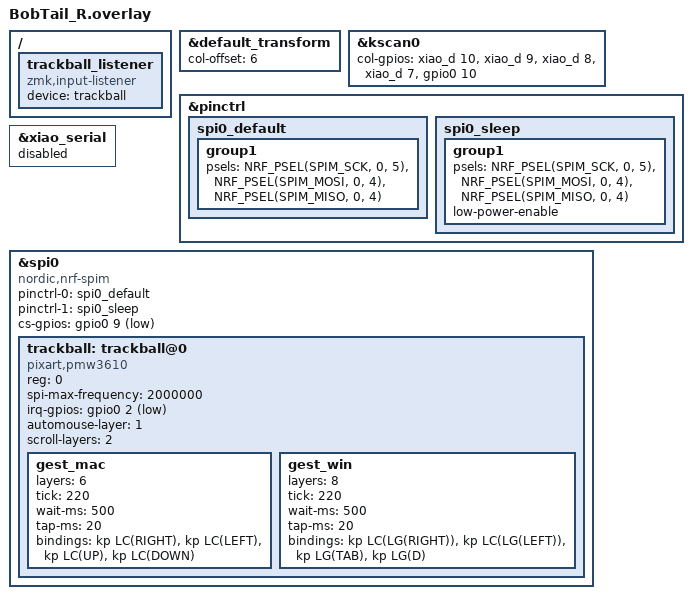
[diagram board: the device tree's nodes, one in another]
#include "BobTail.dtsi"
#include <dt-bindings/zmk/keys.h>

&default_transform {
    col-offset = <6>;
};

&kscan0 {
        col-gpios
            = <&xiao_d 10 GPIO_ACTIVE_HIGH>
            , <&xiao_d 9 GPIO_ACTIVE_HIGH> 
            , <&xiao_d 8 GPIO_ACTIVE_HIGH> 
            , <&xiao_d 7 GPIO_ACTIVE_HIGH> 
            , <&gpio0 10 GPIO_ACTIVE_HIGH>
            ;
};

/ {
    trackball_listener {
        compatible = "zmk,input-listener";
        device = <&trackball>;

    };
};

&pinctrl {
    spi0_default: spi0_default {
        group1 {
            psels = <NRF_PSEL(SPIM_SCK, 0, 5)>,
                <NRF_PSEL(SPIM_MOSI, 0, 4)>,
                <NRF_PSEL(SPIM_MISO, 0, 4)>;
        };
    };

    spi0_sleep: spi0_sleep {
        group1 {
            psels = <NRF_PSEL(SPIM_SCK, 0, 5)>,
                <NRF_PSEL(SPIM_MOSI, 0, 4)>,
                <NRF_PSEL(SPIM_MISO, 0, 4)>;
            low-power-enable;
        };
    };
};

&xiao_serial { status = "disabled"; };

&spi0 {
    status = "okay";
    compatible = "nordic,nrf-spim";
    pinctrl-0 = <&spi0_default>;
    pinctrl-1 = <&spi0_sleep>;
    pinctrl-names = "default", "sleep";
    cs-gpios = <&gpio0 9 GPIO_ACTIVE_LOW>;

    trackball: trackball@0 {
        status = "okay";
        compatible = "pixart,pmw3610";
        reg = <0>;
        spi-max-frequency = <2000000>;
        irq-gpios = <&gpio0 2 (GPIO_ACTIVE_LOW | GPIO_PULL_UP)>;
        /* BobTail.keymap のレイヤー番号と対応 (MOUSE=1 / SCRL=2 / GEST=6 / GESTW=8)。
           NAV や NUM より低い番号にしておくことで、レイヤーを押している
           最中にボールへ触れてもキー割り当てが上書きされない */
        automouse-layer = <1>;
        scroll-layers = <2>;

        /* Gesture 押し中はカーソルを動かさず、フリックをショートカットにする。
           bindings の順はドライバ固定: +X / -X / -Y / +Y
           tick は大きめにして、1 フリックで 2 回発火しないようにする */
        gest_mac {
            layers = <6>;
            tick = <220>;
            wait-ms = <500>;
            tap-ms = <20>;
            bindings = <&kp LC(RIGHT) &kp LC(LEFT) &kp LC(UP) &kp LC(DOWN)>;
        };

        gest_win {
            layers = <8>;
            tick = <220>;
            wait-ms = <500>;
            tap-ms = <20>;
            bindings = <&kp LC(LG(RIGHT)) &kp LC(LG(LEFT)) &kp LG(TAB) &kp LG(D)>;
        };
    };
};
